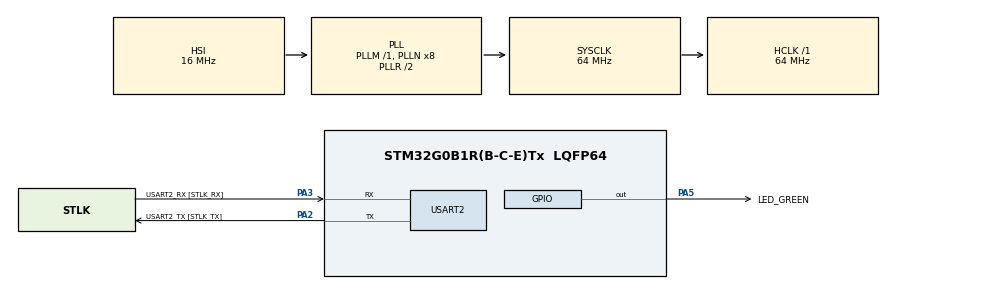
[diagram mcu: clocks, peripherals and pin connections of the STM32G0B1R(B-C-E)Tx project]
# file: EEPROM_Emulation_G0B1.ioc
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Mcu.Family=STM32G0
Mcu.Name=STM32G0B1R(B-C-E)Tx
Mcu.Package=LQFP64
NVIC.FLASH_IRQn=true\:0\:0\:false\:false\:true\:true\:true\:true
NVIC.PVD_VDDIO2_IRQn=true\:0\:0\:false\:false\:true\:true\:true\:true
NVIC.USART2_LPUART2_IRQn=true\:0\:0\:false\:false\:true\:true\:true\:true
PA13.GPIO_Label=TMS
PA13.Mode=Serial_Wire
PA13.Signal=SYS_SWDIO
PA14-BOOT0.GPIO_Label=TCK
PA14-BOOT0.Mode=Serial_Wire
PA14-BOOT0.Signal=SYS_SWCLK
PA2.GPIO_Label=USART2_TX [STLK_TX]
PA2.Mode=Asynchronous
PA2.Signal=USART2_TX
PA3.GPIO_Label=USART2_RX [STLK_RX]
PA3.Mode=Asynchronous
PA3.Signal=USART2_RX
PA5.GPIO_Label=LED_GREEN
PA5.GPIO_Speed=GPIO_SPEED_FREQ_HIGH
PA5.Signal=GPIO_Output
PC13.Mode=SYS_WakeUp1
PC13.Signal=SYS_WKUP2
PC14-OSC32_IN\ (PC14).Mode=LSE-External-Oscillator
PC14-OSC32_IN\ (PC14).Signal=RCC_OSC32_IN
PC15-OSC32_OUT\ (PC15).Mode=LSE-External-Oscillator
PC15-OSC32_OUT\ (PC15).Signal=RCC_OSC32_OUT
PF0-OSC_IN\ (PF0).GPIO_Label=MCO
PF0-OSC_IN\ (PF0).Mode=HSE-External-Clock-Source
PF0-OSC_IN\ (PF0).Signal=RCC_OSC_IN
ProjectManager.HeapSize=0x200
ProjectManager.StackSize=0x400
ProjectManager.TargetToolchain=STM32CubeIDE
RCC.ADCFreq_Value=64000000
RCC.AHBFreq_Value=64000000
RCC.CortexFreq_Value=64000000
RCC.EXTERNAL_CLOCK_VALUE=12288000
RCC.HCLKFreq_Value=64000000
RCC.HSE_VALUE=8000000
RCC.HSI48_VALUE=48000000
RCC.HSI_VALUE=16000000
RCC.SYSCLKFreq_VALUE=64000000
RCC.SYSCLKSource=RCC_SYSCLKSOURCE_PLLCLK
RCC.USBFreq_Value=48000000
RCC.VCOOutputFreq_Value=128000000
USART2.VirtualMode-Asynchronous=VM_ASYNC
VP_CRC_VS_CRC.Mode=CRC_Activate
board=NUCLEO-G0B1RE

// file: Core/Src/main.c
/* USER CODE BEGIN Header */
/**
  ******************************************************************************
  * @file           : main.c
  * @brief          : Main program body
  ******************************************************************************
  * @attention
  *
  * Copyright (c) 2022 STMicroelectronics.
  * All rights reserved.
  *
  * This software is licensed under terms that can be found in the LICENSE file
  * in the root directory of this software component.
  * If no LICENSE file comes with this software, it is provided AS-IS.
  *
  ******************************************************************************
  */
/* USER CODE END Header */
#include "main.h"

/* USER CODE BEGIN Includes */
#include "stm32g0b1xx.h"
/* USER CODE END Includes */

/* USER CODE BEGIN PD */
#define FLAG_WUF PWR_FLAG_WUF2
/* USER CODE END PD */

UART_HandleTypeDef huart2;

/* USER CODE BEGIN PV */
uint32_t Index = 1;
__IO uint32_t ErasingOnGoing = 0;
uint32_t a_VarDataTab[NB_OF_VARIABLES] = {0};
uint32_t VarValue = 0;

uint8_t a_VarDataTab_8bit[NB_OF_VARIABLES] = {0};
uint8_t VarValue_8bit = 0;
/* USER CODE END PV */

void SystemClock_Config(void);
static void MX_GPIO_Init(void);
static void MX_USART2_UART_Init(void);
static void MX_CRC_Init(void);
/* USER CODE BEGIN PFP */
static void PVD_Config(void);
/* USER CODE END PFP */

int main(void)
{
  /* USER CODE BEGIN 1 */
	EE_Status ee_status = EE_OK;

  /* USER CODE END 1 */

  /* MCU Configuration--------------------------------------------------------*/

  /* Reset of all peripherals, Initializes the Flash interface and the Systick. */
  HAL_Init();

  /* Configure the system clock */
  SystemClock_Config();

  /* Initialize all configured peripherals */
  MX_GPIO_Init();
  MX_USART2_UART_Init();
  /* USER CODE BEGIN 2 */
  /* Enable and set FLASH Interrupt priority */
    /* FLASH interrupt is used for the purpose of pages clean up under interrupt */
    HAL_NVIC_SetPriority(FLASH_IRQn, 0, 0);
    HAL_NVIC_EnableIRQ(FLASH_IRQn);

    /* Unlock the Flash Program Erase controller */
    HAL_FLASH_Unlock();

    /* Enable Power Control clock */
    __HAL_RCC_PWR_CLK_ENABLE();
    HAL_PWR_DisableWakeUpPin(PWR_WAKEUP_PIN2);

    /* Configure Programmable Voltage Detector (PVD) (optional) */
    /* PVD interrupt is used to suspend the current application flow in case
       a power-down is detected, allowing the flash interface to finish any
       ongoing operation before a reset is triggered. */
    PVD_Config();

    /* Configure LED_KO & LED_OK */
    HAL_GPIO_WritePin(LED_GREEN_GPIO_Port, LED_GREEN_Pin, GPIO_PIN_RESET);

    /* Activate NMI generation when two errors are detected */
    __HAL_FLASH_ENABLE_IT(FLASH_IT_ECCC);

    /* Set EEPROM emulation firmware to erase all potentially incompletely erased
       pages if the system came from an asynchronous reset. Conditional erase is
       safe to use if all Flash operations where completed before the system reset */
    if(__HAL_PWR_GET_FLAG(PWR_FLAG_SB) == RESET)
    {
      /* Blink LED_OK (Green) twice at startup */
      HAL_GPIO_TogglePin(LED_GREEN_GPIO_Port, LED_GREEN_Pin);
      HAL_Delay(100);
      HAL_GPIO_TogglePin(LED_GREEN_GPIO_Port, LED_GREEN_Pin);
      HAL_Delay(100);
      HAL_GPIO_TogglePin(LED_GREEN_GPIO_Port, LED_GREEN_Pin);
      HAL_Delay(100);
      HAL_GPIO_TogglePin(LED_GREEN_GPIO_Port, LED_GREEN_Pin);

      /* System reset comes from a power-on reset: Forced Erase */
      /* Initialize EEPROM emulation driver (mandatory) */
      ee_status = EE_Init(EE_FORCED_ERASE);
      if(ee_status != EE_OK) {Error_Handler();}
    }
    else
    {
      /* Clear the Standby flag */
      __HAL_PWR_CLEAR_FLAG(PWR_FLAG_SB);

      /* Check and Clear the Wakeup flag */
      if (__HAL_PWR_GET_FLAG(FLAG_WUF) != RESET)
      {
        __HAL_PWR_CLEAR_FLAG(FLAG_WUF);
      }

      /* Blink LED_OK (Green) upon wakeup */
      HAL_GPIO_TogglePin(LED_GREEN_GPIO_Port, LED_GREEN_Pin);
      HAL_Delay(100);
      HAL_GPIO_TogglePin(LED_GREEN_GPIO_Port, LED_GREEN_Pin);

      /* System reset comes from a STANDBY wakeup: Conditional Erase*/
      /* Initialize EEPROM emulation driver (mandatory) */
      ee_status = EE_Init(EE_CONDITIONAL_ERASE);
      if(ee_status != EE_OK) {Error_Handler();}
    }

    /* Store 10 values of all variables in EEPROM, ascending order */
    for (VarValue = 1; VarValue <= 10; VarValue++)
    {
      for (Index = 1; Index < NB_OF_VARIABLES+1; Index++)
      {
        /* Wait any cleanup is completed before accessing flash again */
        while (ErasingOnGoing == 1) { }

//        ee_status = EE_WriteVariable32bits(Index, Index*VarValue);
//        ee_status|= EE_ReadVariable32bits(Index, &a_VarDataTab[Index-1]);

        VarValue_8bit += VarValue;
        ee_status = EE_WriteVariable8bits(Index, (uint8_t)Index*VarValue_8bit);
        ee_status|= EE_ReadVariable8bits(Index, (uint8_t*)&a_VarDataTab_8bit[Index-1]);
//        if (Index*VarValue != a_VarDataTab[Index-1]) {Error_Handler();}
        if (Index*VarValue_8bit != a_VarDataTab_8bit[Index-1]) {Error_Handler();}

        /* Start cleanup IT mode, if cleanup is needed */
        if ((ee_status & EE_STATUSMASK_CLEANUP) == EE_STATUSMASK_CLEANUP) {ErasingOnGoing = 1;ee_status|= EE_CleanUp_IT();}
        if ((ee_status & EE_STATUSMASK_ERROR) == EE_STATUSMASK_ERROR) {Error_Handler();}
      }
    }

    /* Read all the variables */
    for (Index = 1; Index < NB_OF_VARIABLES+1; Index++)
    {
      ee_status = EE_ReadVariable32bits(Index, &VarValue);
      if (VarValue != a_VarDataTab[Index-1]) {Error_Handler();}
      if (ee_status != EE_OK) {Error_Handler();}
    }

    /* Store 1000 values of Variable1,2,3 in EEPROM */
    for (VarValue = 1; VarValue <= 1000; VarValue++)
    {
      while (ErasingOnGoing == 1) { }

      ee_status = EE_WriteVariable32bits(1, VarValue);
      ee_status|= EE_ReadVariable32bits(1, &a_VarDataTab[0]);
      if (VarValue != a_VarDataTab[0]) {Error_Handler();}

      ee_status|= EE_WriteVariable32bits(2, ~VarValue);
      ee_status|= EE_ReadVariable32bits(2, &a_VarDataTab[1]);
      if (~VarValue != a_VarDataTab[1]) {Error_Handler();}

      ee_status|= EE_WriteVariable32bits(3, VarValue << 1);
      ee_status|= EE_ReadVariable32bits(3, &a_VarDataTab[2]);
      if ((VarValue << 1) != a_VarDataTab[2]) {Error_Handler();}

      /* Start cleanup polling mode, if cleanup is needed */
      if ((ee_status & EE_STATUSMASK_CLEANUP) == EE_STATUSMASK_CLEANUP) {ErasingOnGoing = 0;ee_status|= EE_CleanUp();}
      if ((ee_status & EE_STATUSMASK_ERROR) == EE_STATUSMASK_ERROR) {Error_Handler();}
    }

    /* Read all the variables */
    for (Index = 1; Index < NB_OF_VARIABLES+1; Index++)
    {
      ee_status = EE_ReadVariable32bits(Index, &VarValue);
      if (VarValue != a_VarDataTab[Index-1]) {Error_Handler();}
      if (ee_status != EE_OK) {Error_Handler();}
    }

    /* Test is completed successfully */
    /* Lock the Flash Program Erase controller */
    HAL_FLASH_Lock();
  /* USER CODE END 2 */

  /* Infinite loop */
  while (1)
  {

  }
}

void SystemClock_Config(void)
{
  RCC_OscInitTypeDef RCC_OscInitStruct = {0};
  RCC_ClkInitTypeDef RCC_ClkInitStruct = {0};

  /** Configure the main internal regulator output voltage
  */
  HAL_PWREx_ControlVoltageScaling(PWR_REGULATOR_VOLTAGE_SCALE1);

  /** Initializes the RCC Oscillators according to the specified parameters
  * in the RCC_OscInitTypeDef structure.
  */
  RCC_OscInitStruct.OscillatorType = RCC_OSCILLATORTYPE_HSI;
  RCC_OscInitStruct.HSIState = RCC_HSI_ON;
  RCC_OscInitStruct.HSIDiv = RCC_HSI_DIV1;
  RCC_OscInitStruct.HSICalibrationValue = RCC_HSICALIBRATION_DEFAULT;
  RCC_OscInitStruct.PLL.PLLState = RCC_PLL_ON;
  RCC_OscInitStruct.PLL.PLLSource = RCC_PLLSOURCE_HSI;
  RCC_OscInitStruct.PLL.PLLM = RCC_PLLM_DIV1;
  RCC_OscInitStruct.PLL.PLLN = 8;
  RCC_OscInitStruct.PLL.PLLP = RCC_PLLP_DIV2;
  RCC_OscInitStruct.PLL.PLLQ = RCC_PLLQ_DIV2;
  RCC_OscInitStruct.PLL.PLLR = RCC_PLLR_DIV2;
  if (HAL_RCC_OscConfig(&RCC_OscInitStruct) != HAL_OK)
  {
    Error_Handler();
  }

  /** Initializes the CPU, AHB and APB buses clocks
  */
  RCC_ClkInitStruct.ClockType = RCC_CLOCKTYPE_HCLK|RCC_CLOCKTYPE_SYSCLK
                              |RCC_CLOCKTYPE_PCLK1;
  RCC_ClkInitStruct.SYSCLKSource = RCC_SYSCLKSOURCE_PLLCLK;
  RCC_ClkInitStruct.AHBCLKDivider = RCC_SYSCLK_DIV1;
  RCC_ClkInitStruct.APB1CLKDivider = RCC_HCLK_DIV1;

  if (HAL_RCC_ClockConfig(&RCC_ClkInitStruct, FLASH_LATENCY_2) != HAL_OK)
  {
    Error_Handler();
  }
}

static void MX_CRC_Init(void)
{

  /* Peripheral clock enable */
  LL_AHB1_GRP1_EnableClock(LL_AHB1_GRP1_PERIPH_CRC);

  LL_CRC_SetInputDataReverseMode(CRC, LL_CRC_INDATA_REVERSE_NONE);
  LL_CRC_SetOutputDataReverseMode(CRC, LL_CRC_OUTDATA_REVERSE_NONE);
  LL_CRC_SetPolynomialCoef(CRC, LL_CRC_DEFAULT_CRC32_POLY);
  LL_CRC_SetPolynomialSize(CRC, LL_CRC_POLYLENGTH_32B);
  LL_CRC_SetInitialData(CRC, LL_CRC_DEFAULT_CRC_INITVALUE);

}

static void MX_USART2_UART_Init(void)
{

  huart2.Instance = USART2;
  huart2.Init.BaudRate = 115200;
  huart2.Init.WordLength = UART_WORDLENGTH_8B;
  huart2.Init.StopBits = UART_STOPBITS_1;
  huart2.Init.Parity = UART_PARITY_NONE;
  huart2.Init.Mode = UART_MODE_TX_RX;
  huart2.Init.HwFlowCtl = UART_HWCONTROL_NONE;
  huart2.Init.OverSampling = UART_OVERSAMPLING_16;
  huart2.Init.OneBitSampling = UART_ONE_BIT_SAMPLE_DISABLE;
  huart2.Init.ClockPrescaler = UART_PRESCALER_DIV1;
  huart2.AdvancedInit.AdvFeatureInit = UART_ADVFEATURE_NO_INIT;
  if (HAL_UART_Init(&huart2) != HAL_OK)
  {
    Error_Handler();
  }
  if (HAL_UARTEx_SetTxFifoThreshold(&huart2, UART_TXFIFO_THRESHOLD_1_8) != HAL_OK)
  {
    Error_Handler();
  }
  if (HAL_UARTEx_SetRxFifoThreshold(&huart2, UART_RXFIFO_THRESHOLD_1_8) != HAL_OK)
  {
    Error_Handler();
  }
  if (HAL_UARTEx_DisableFifoMode(&huart2) != HAL_OK)
  {
    Error_Handler();
  }

}

static void MX_GPIO_Init(void)
{
  GPIO_InitTypeDef GPIO_InitStruct = {0};

  /* GPIO Ports Clock Enable */
  __HAL_RCC_GPIOC_CLK_ENABLE();
  __HAL_RCC_GPIOF_CLK_ENABLE();
  __HAL_RCC_GPIOA_CLK_ENABLE();

  /*Configure GPIO pin Output Level */
  HAL_GPIO_WritePin(LED_GREEN_GPIO_Port, LED_GREEN_Pin, GPIO_PIN_RESET);

  /*Configure GPIO pin : LED_GREEN_Pin */
  GPIO_InitStruct.Pin = LED_GREEN_Pin;
  GPIO_InitStruct.Mode = GPIO_MODE_OUTPUT_PP;
  GPIO_InitStruct.Pull = GPIO_NOPULL;
  GPIO_InitStruct.Speed = GPIO_SPEED_FREQ_HIGH;
  HAL_GPIO_Init(LED_GREEN_GPIO_Port, &GPIO_InitStruct);

}

/* USER CODE BEGIN 4 */
/**
  * @brief  Programmable Voltage Detector (PVD) Configuration
  *         PVD set to level 6 for a threshold around 2.9V.
  * @param  None
  * @retval None
  */
static void PVD_Config(void)
{
  PWR_PVDTypeDef sConfigPVD;
  sConfigPVD.PVDLevel = PWR_PVDLEVEL_6;
  sConfigPVD.Mode     = PWR_PVD_MODE_IT_RISING;
  if (HAL_PWR_ConfigPVD(&sConfigPVD) != HAL_OK) {Error_Handler();}

  /* Enable PVD */
  HAL_PWR_EnablePVD();

  /* Enable and set PVD Interrupt priority */
  HAL_NVIC_SetPriority(PVD_VDDIO2_IRQn, 0, 0);
  HAL_NVIC_EnableIRQ(PVD_VDDIO2_IRQn);
}

/**
  * @brief  FLASH end of operation interrupt callback.
  * @param  ReturnValue: The value saved in this parameter depends on the ongoing procedure
  *                  Mass Erase: Bank number which has been requested to erase
  *                  Page Erase: Page which has been erased
  *                  Program: Address which was selected for data program
  * @retval None
  */
void HAL_FLASH_EndOfOperationCallback(uint32_t ReturnValue)
{
  /* Call CleanUp callback when all requested pages have been erased */
  if( (ReturnValue == (START_PAGE+PAGES_NUMBER/2-1)) || (ReturnValue == (START_PAGE+PAGES_NUMBER-1)) )
  {
    EE_EndOfCleanup_UserCallback();
  }
}

/**
  * @brief  Clean Up end of operation interrupt callback.
  * @param  None
  * @retval None
  */
void EE_EndOfCleanup_UserCallback(void)
{
  ErasingOnGoing = 0;
}
/* USER CODE END 4 */

void Error_Handler(void)
{
  __disable_irq();
  while (1)
  {
  }
}
